# nrf9220_flpr register map
Vendor: Nordic Semiconductor; Series: nRF92; File version: 1
Registers are 32-bit, read-write, reset 0x0 unless marked. A register's access mark holds for its fields unless they carry their own. Offsets are from the block's base; [hi:lo] are bit positions; lines under a group give offsets from that group; {n}, {i} and the like mark numbered series.

## GLOBAL_TSGEN — Timestamp generator
Base 0xBF041000
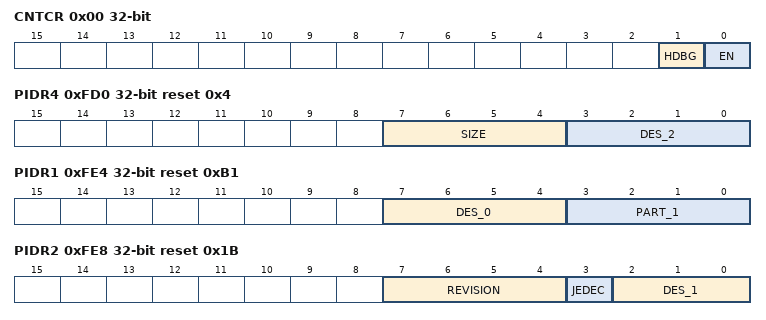
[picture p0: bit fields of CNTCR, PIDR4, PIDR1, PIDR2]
0x00 CNTCR — Counter Control Register
  [1] HDBG — Halt on Debug
    0=Disabled (Do not halt on debug, HLTDBG signal into the counter has no effect.); 1=Enabled (Halt on debug, when HLTDBG is driven HIGH, the count value is held static.)
  [0] EN — Counter enable
    0=Disabled (Unspecified); 1=Enabled (Unspecified)
0x04 CNTSR ro — Counter Status Register
  [1] DBGH — Debug halted
0x08 CNTCVL — Current Counter Value Lower register
  [31:0] CNTCVL_L_32 — Current value of Counter, lower 32 bits
0x0C CNTCVU — Current Counter Value Upper register
  [31:0] CNTCVU_U_32 — Current value of Counter, upper 32 bits
0x20 CNTFID0 — Base Frequency ID
  [31:0] FREQ — Frequency in number of ticks per second (up to 4 GHz)
0xFD0 PIDR4 ro reset 0x4 — Peripheral ID4 Register
  [7:4] SIZE — This is a 4-bit value that indicates the total contiguous size of the memory window used by this component in powers of 2 from the standard 4KB. If a component only requires the standard 4KB, this must read as 0x0, 4KB only. For 8KB set to 0x1, for 16KB set to 0x2, for 32KB set to 0x3, and so on.
  [3:0] DES_2 — JEDEC continuation code indicating the designer of the component, together with the identity code.
0xFE0 PIDR0 ro reset 0x1 — Peripheral ID0 Register
  [7:0] PART_0 — Bits [7:0] of the component part number. This is selected by the designer of the component.
0xFE4 PIDR1 ro reset 0xB1 — Peripheral ID1 Register
  [7:4] DES_0 — Bits [3:0] of the JEDEC identity code indicating the designer of the component, together with the continuation code.
  [3:0] PART_1 — Bits [11:8] of the component part number. This is selected by the designer of the component.
0xFE8 PIDR2 ro reset 0x1B — Peripheral ID2 Register
  [7:4] REVISION — The Revision field is an incremental value starting at 0x0 for the first design of this component. This only increases by 1 for both major and minor revisions and is used as a look-up to establish the exact major and minor revision.
  [3] JEDEC — Always set. Indicates that a JEDEC assigned value is used.
  [2:0] DES_1 — Bits [6:4] of the JEDEC identity code indicating the designer of the component, together with the continuation code.
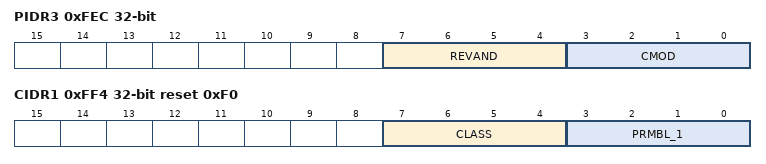
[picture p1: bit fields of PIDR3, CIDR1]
0xFEC PIDR3 ro — Peripheral ID3 Register
  [7:4] REVAND — This field indicates minor errata fixes specific to this design, for example metal fixes after implementation. In most cases this field is zero. It is recommended that component designers ensure this field can be changed by a metal fix if required, for example by driving it from registers that reset to zero.
  [3:0] CMOD — Where the component is reusable IP, this value indicates if the customer has modified the behavior of the component. In most cases this field is zero.
0xFF0 CIDR0 ro reset 0xD — Component ID0 Register
  [7:0] PRMBL_0 — Contains bits[7:0] of the component identification code.
0xFF4 CIDR1 ro reset 0xF0 — Component ID1 Register
  [7:4] CLASS — Class of the component, for example, ROM table or CoreSight component.
  [3:0] PRMBL_1 — Contains bits[11:8] of the component identification code.
0xFF8 CIDR2 ro reset 0x5 — Component ID2 Register
  [7:0] PRMBL_2 — Contains bits[23:16] of the component identification code.
0xFFC CIDR3 ro reset 0xB1 — Component ID3 Register
  [7:0] PRMBL_3 — Contains bits[31:24] of the component identification code.

## VPRCLIC — VPR CLIC registers
Base 0xF0000000
0x00 CLIC group — Unspecified
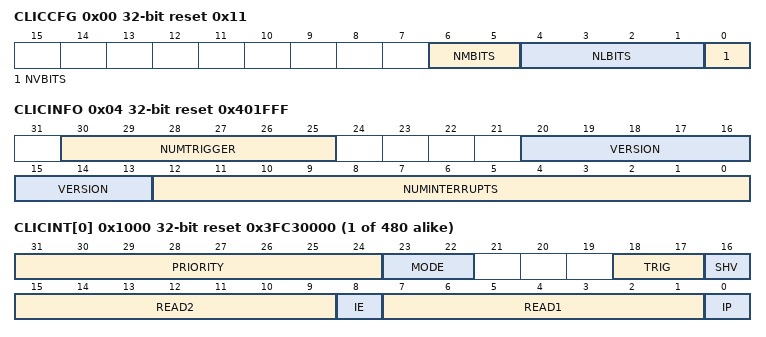
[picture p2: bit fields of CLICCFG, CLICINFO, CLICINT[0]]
  0x00 CLICCFG ro reset 0x11 — CLIC configuration.
    [6:5] NMBITS — Interrupt privilege mode.
      0=ModeM (All interrupts are M-mode only)
    [4:1] NLBITS — Interrupt level encoding.
      8=Eight (8 bits = interrupt levels encoded in eight bits)
    [0] NVBITS — Selective interrupt hardware vectoring.
      1=Implemented (Selective interrupt hardware vectoring is implemented)
  0x04 CLICINFO ro reset 0x401FFF — CLIC information.
    [30:25] NUMTRIGGER — Number of maximum interrupt triggers supported
    [20:13] VERSION
    [12:0] NUMINTERRUPTS — Maximum number of interrupts supported.
  {0x1000+4j} CLICINT[{j}] (j=0..479) reset 0x3FC30000 — Description collection: Interrupt control register for IRQ number [n].
    [31:24] PRIORITY — Interrupt priority level
      63=PRIO3F (Priority level 0x3F); 127=PRIO7F (Priority level 0x7F); 191=PRIOBF (Priority level 0xBF); 255=PRIOFF (Priority level 0xFF); 63=PRIOLEVEL0 (Deprecated enumerator - Priority level 0); 127=PRIOLEVEL1 (Deprecated enumerator - Priority level 1); 191=PRIOLEVEL2 (Deprecated enumerator - Priority level 2); 255=PRIOLEVEL3 (Deprecated enumerator - Priority level 3)
    [23:22] MODE ro — Privilege mode.
      3=MachineMode
    [18:17] TRIG ro — Trigger type and polarity for each interrupt input.
      1=EdgeTriggered (Interrupts are edge-triggered)
    [16] SHV ro — Selective Hardware Vectoring.
      1=Vectored (Hardware vectored)
    [15:9] READ2 ro — Read as 0, write ignored.
    [8] IE — Interrupt enable bit.
      0=Disabled (Interrupt disabled); 1=Enabled (Interrupt enabled)
    [7:1] READ1 ro — Read as 0, write ignored.
    [0] IP — Interrupt Pending bit.
      0=NotPending (Interrupt not pending); 1=Pending (Interrupt pending)
